# AT90PWM3B register map
Vendor: Atmel; File version: 1.0
CPU: other r0p0, little endian, no MPU, no FPU, 4 interrupt priority bits
Registers are 8-bit, read-write, reset 0x0 unless marked. A register's access mark holds for its fields unless they carry their own. Offsets are from the block's base; [hi:lo] are bit positions; {n}, {i} and the like mark numbered series.

## ADC — Analog-to-Digital Converter
Base 0x00000076
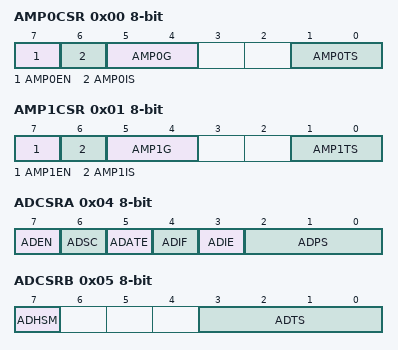
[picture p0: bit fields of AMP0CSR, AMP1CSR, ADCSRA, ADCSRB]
0x00 AMP0CSR
  [7] AMP0EN, [6] AMP0IS, [5:4] AMP0G, [1:0] AMP0TS
0x01 AMP1CSR
  [7] AMP1EN, [6] AMP1IS, [5:4] AMP1G, [1:0] AMP1TS
0x02 ADC 16-bit (reset mask 0xFF) — ADC Data Register Bytes
  [15:0] ADC — ADC Data Register
0x04 ADCSRA — The ADC Control and Status register
  [7] ADEN — ADC Enable
  [6] ADSC — ADC Start Conversion
  [5] ADATE — ADC Auto Trigger Enable
  [4] ADIF — ADC Interrupt Flag
  [3] ADIE — ADC Interrupt Enable
  [2:0] ADPS — ADC Prescaler Select Bits
0x05 ADCSRB — ADC Control and Status Register B
  [7] ADHSM — ADC High Speed Mode
  [3:0] ADTS — ADC Auto Trigger Source
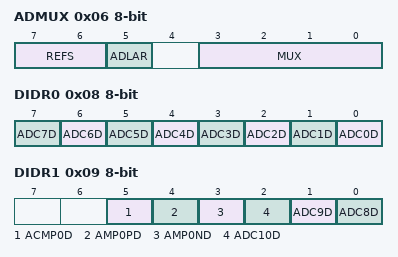
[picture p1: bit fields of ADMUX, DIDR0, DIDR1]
0x06 ADMUX — The ADC multiplexer Selection Register
  [7:6] REFS — Reference Selection Bits
    0=AREF, Internal Vref turned off; 1=AVCC with external capacitor at AREF pin; 3=Internal 2.56V Voltage Reference with external capacitor at AREF pin
  [5] ADLAR — Left Adjust Result
  [3:0] MUX — Analog Channel and Gain Selection Bits
0x08 DIDR0 — Digital Input Disable Register 0
  [n] ADC{n}D (n=0..7)
0x09 DIDR1 — Digital Input Disable Register 1
  [5] ACMP0D, [4] AMP0PD, [3] AMP0ND, [2] ADC10D, [1] ADC9D, [0] ADC8D

## BOOT_LOAD — Bootloader
Base 0x00000057
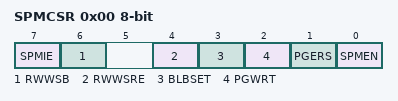
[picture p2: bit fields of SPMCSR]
0x00 SPMCSR — Store Program Memory Control Register
  [7] SPMIE — SPM Interrupt Enable
  [6] RWWSB — Read While Write Section Busy
  [4] RWWSRE — Read While Write section read enable
  [3] BLBSET — Boot Lock Bit Set
  [2] PGWRT — Page Write
  [1] PGERS — Page Erase
  [0] SPMEN — Store Program Memory Enable

## CPU — CPU Registers
Base 0x00000039
0x00 GPIOR1 — General Purpose IO Register 1
0x01 GPIOR2 — General Purpose IO Register 2
0x02 GPIOR3 — General Purpose IO Register 3
0x05 GPIOR0 — General Purpose IO Register 0
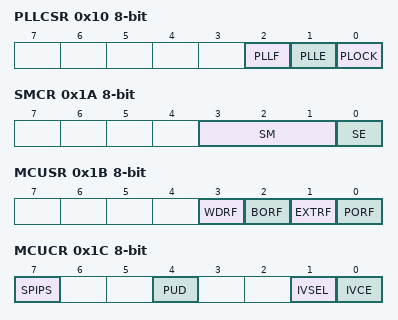
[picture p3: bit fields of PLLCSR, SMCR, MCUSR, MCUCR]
0x10 PLLCSR — PLL Control And Status Register
  [2] PLLF — PLL Factor
  [1] PLLE — PLL Enable
  [0] PLOCK — PLL Lock Detector
0x1A SMCR — Sleep Mode Control Register
  [3:1] SM — Sleep Mode Select bits
    0=IDLE; 1=ADC (ADC Noise Reduction (If Available)); 2=PDOWN (Power Down); 6=STDBY (Standby)
  [0] SE — Sleep Enable
0x1B MCUSR — MCU Status Register
  [3] WDRF — Watchdog Reset Flag
  [2] BORF — Brown-out Reset Flag
  [1] EXTRF — External Reset Flag
  [0] PORF — Power-on reset flag
0x1C MCUCR — MCU Control Register
  [7] SPIPS — SPI Pin Select
  [4] PUD — Pull-up disable
  [1] IVSEL — Interrupt Vector Select
  [0] IVCE — Interrupt Vector Change Enable
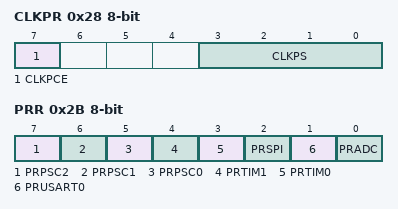
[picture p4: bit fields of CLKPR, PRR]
0x28 CLKPR
  [7] CLKPCE
  [3:0] CLKPS
    0=1; 1=2; 2=4; 3=8; 4=16; 5=32; 6=64; 7=128; 8=256
0x2B PRR — Power Reduction Register
  [7] PRPSC2 — Power Reduction PSC2
  [6] PRPSC1 — Power Reduction PSC1
  [5] PRPSC0 — Power Reduction PSC0
  [4] PRTIM1 — Power Reduction Timer/Counter1
  [3] PRTIM0 — Power Reduction Timer/Counter0
  [2] PRSPI — Power Reduction Serial Peripheral Interface
  [1] PRUSART0 — Power Reduction USART
  [0] PRADC — Power Reduction ADC
0x2D OSCCAL — Oscillator Calibration Value
  [7:0] OSCCAL — Oscillator Calibration

## DAC — Digital-to-Analog Converter
Base 0x000000AA
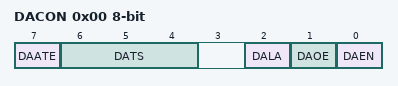
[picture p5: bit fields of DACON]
0x00 DACON — DAC Control Register
  [7] DAATE — DAC Auto Trigger Enable Bit
  [6:4] DATS — DAC Trigger Selection Bits
    0=Analog Comparator 0; 1=Analog Comparator 1; 2=External Interrupt Request 0; 3=Timer/Counter0 Compare Match A; 4=Timer/Counter0 Overflow; 5=Timer/Counter1 Compare Match B; 6=Timer/Counter1 Overflow; 7=Timer/Counter1 Capture Event
  [2] DALA — DAC Left Adjust
  [1] DAOE — DAC Output Enable
  [0] DAEN — DAC Enable Bit
0x01 DAC 16-bit (reset mask 0xFF) — DAC Data Register
  [15:0] DAC — DAC Data Register Bits

## EEPROM
Base 0x0000003F
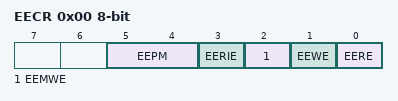
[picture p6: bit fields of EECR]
0x00 EECR — EEPROM Control Register
  [5:4] EEPM — EEPROM Programming Mode
  [3] EERIE — EEPROM Ready Interrupt Enable
  [2] EEMWE — EEPROM Master Write Enable
  [1] EEWE — EEPROM Write Enable
  [0] EERE — EEPROM Read Enable
0x01 EEDR — EEPROM Data Register
  [7:0] EEDR — EEPROM Data Bits
0x02 EEAR 16-bit (reset mask 0xFF) — EEPROM Read/Write Access Bytes
  [11:0] EEAR — EEPROM Address bytes
